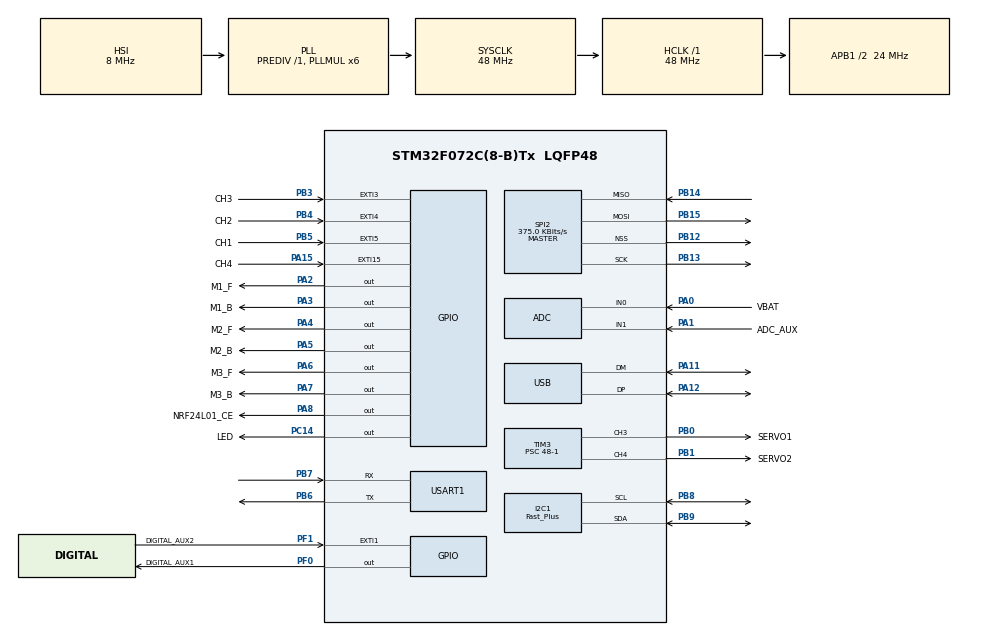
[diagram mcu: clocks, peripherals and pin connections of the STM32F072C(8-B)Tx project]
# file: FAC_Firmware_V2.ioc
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ADC.ContinuousConvMode=ENABLE
ADC.DMAContinuousRequests=ENABLE
ADC.EOCSelection=ADC_EOC_SEQ_CONV
ADC.SamplingTime=ADC_SAMPLETIME_55CYCLES_5
Dma.ADC.0.Direction=DMA_PERIPH_TO_MEMORY
Dma.ADC.0.Instance=DMA1_Channel1
Dma.ADC.0.MemDataAlignment=DMA_MDATAALIGN_HALFWORD
Dma.ADC.0.MemInc=DMA_MINC_ENABLE
Dma.ADC.0.Mode=DMA_CIRCULAR
Dma.ADC.0.PeriphDataAlignment=DMA_PDATAALIGN_HALFWORD
Dma.ADC.0.PeriphInc=DMA_PINC_DISABLE
Dma.ADC.0.Priority=DMA_PRIORITY_LOW
Dma.Request0=ADC
Dma.Request1=TIM1_UP
Dma.TIM1_UP.1.Direction=DMA_MEMORY_TO_PERIPH
Dma.TIM1_UP.1.Instance=DMA1_Channel5
Dma.TIM1_UP.1.MemDataAlignment=DMA_MDATAALIGN_WORD
Dma.TIM1_UP.1.MemInc=DMA_MINC_ENABLE
Dma.TIM1_UP.1.Mode=DMA_CIRCULAR
Dma.TIM1_UP.1.PeriphDataAlignment=DMA_PDATAALIGN_WORD
Dma.TIM1_UP.1.PeriphInc=DMA_PINC_DISABLE
Dma.TIM1_UP.1.Priority=DMA_PRIORITY_LOW
I2C1.I2C_Speed_Mode=I2C_Fast_Plus
I2C1.Timing=0x00100001
IWDG.Prescaler=IWDG_PRESCALER_32
IWDG.Reload=499
Mcu.Family=STM32F0
Mcu.Name=STM32F072C(8-B)Tx
Mcu.Package=LQFP48
NVIC.DMA1_Channel1_IRQn=true\:0\:0\:false\:false\:true\:false\:true\:true
NVIC.DMA1_Channel4_5_6_7_IRQn=true\:0\:0\:false\:false\:true\:false\:true\:true
NVIC.EXTI2_3_IRQn=true\:0\:0\:false\:false\:true\:true\:true\:true
NVIC.EXTI4_15_IRQn=true\:0\:0\:false\:false\:true\:true\:true\:true
NVIC.USB_IRQn=true\:0\:0\:false\:false\:true\:false\:true\:true
PA0.GPIO_Label=VBAT
PA0.Mode=IN0
PA0.Signal=ADC_IN0
PA1.GPIO_Label=ADC_AUX
PA1.Mode=IN1
PA1.Signal=ADC_IN1
PA11.Mode=Device
PA11.Signal=USB_DM
PA12.Mode=Device
PA12.Signal=USB_DP
PA13.Mode=Serial_Wire
PA13.Signal=SYS_SWDIO
PA14.Mode=Serial_Wire
PA14.Signal=SYS_SWCLK
PA15.GPIO_Label=CH4
PA15.GPIO_ModeDefaultEXTI=GPIO_MODE_IT_RISING_FALLING
PA15.Signal=GPXTI15
PA2.GPIO_Label=M1_F
PA2.Signal=GPIO_Output
PA3.GPIO_Label=M1_B
PA3.Signal=GPIO_Output
PA4.GPIO_Label=M2_F
PA4.Signal=GPIO_Output
PA5.GPIO_Label=M2_B
PA5.Signal=GPIO_Output
PA6.GPIO_Label=M3_F
PA6.Signal=GPIO_Output
PA7.GPIO_Label=M3_B
PA7.Signal=GPIO_Output
PA8.GPIO_Label=NRF24L01_CE
PA8.Signal=GPIO_Output
PB0.GPIO_Label=SERVO1
PB0.Signal=S_TIM3_CH3
PB1.GPIO_Label=SERVO2
PB1.Signal=S_TIM3_CH4
PB12.Mode=NSS_Signal_Hard_Output
PB12.Signal=SPI2_NSS
PB13.Mode=Full_Duplex_Master
PB13.Signal=SPI2_SCK
PB14.Mode=Full_Duplex_Master
PB14.Signal=SPI2_MISO
PB15.Mode=Full_Duplex_Master
PB15.Signal=SPI2_MOSI
PB3.GPIO_Label=CH3
PB3.GPIO_ModeDefaultEXTI=GPIO_MODE_IT_RISING_FALLING
PB3.Signal=GPXTI3
PB4.GPIO_Label=CH2
PB4.GPIO_ModeDefaultEXTI=GPIO_MODE_IT_RISING_FALLING
PB4.Signal=GPXTI4
PB5.GPIO_Label=CH1
PB5.GPIO_ModeDefaultEXTI=GPIO_MODE_IT_RISING_FALLING
PB5.Signal=GPXTI5
PB6.Mode=Asynchronous
PB6.Signal=USART1_TX
PB7.Mode=Asynchronous
PB7.Signal=USART1_RX
PB8.GPIO_FM8=__NULL
PB8.GPIO_Pu=GPIO_NOPULL
PB8.Mode=I2C
PB8.Signal=I2C1_SCL
PB9.GPIO_FM9=__NULL
PB9.GPIO_Pu=GPIO_NOPULL
PB9.Mode=I2C
PB9.Signal=I2C1_SDA
PC14-OSC32_IN.GPIO_Label=LED
PC14-OSC32_IN.Signal=GPIO_Output
PF0-OSC_IN.GPIO_Label=DIGITAL_AUX1
PF0-OSC_IN.Signal=GPIO_Output
PF1-OSC_OUT.GPIO_Label=DIGITAL_AUX2
PF1-OSC_OUT.Signal=GPXTI1
ProjectManager.HeapSize=0x200
ProjectManager.StackSize=0x400
ProjectManager.TargetToolchain=STM32CubeIDE
RCC.AHBFreq_Value=48000000
RCC.APB1CLKDivider=RCC_HCLK_DIV2
RCC.APB1Freq_Value=24000000
RCC.APB1TimFreq_Value=48000000
RCC.HCLKFreq_Value=48000000
RCC.PLLMUL=RCC_PLL_MUL6
RCC.SYSCLKFreq_VALUE=48000000
RCC.SYSCLKSource=RCC_SYSCLKSOURCE_PLLCLK
SH.S_TIM3_CH3.0=TIM3_CH3,PWM Generation3 CH3
SH.S_TIM3_CH4.0=TIM3_CH4,PWM Generation4 CH4
SPI2.BaudRatePrescaler=SPI_BAUDRATEPRESCALER_64
SPI2.CalculateBaudRate=375.0 KBits/s
SPI2.Direction=SPI_DIRECTION_2LINES
SPI2.Mode=SPI_MODE_MASTER
SPI2.VirtualNSS=VM_NSSHARD
SPI2.VirtualType=VM_MASTER
TIM1.TIM_MasterOutputTrigger=TIM_TRGO_UPDATE
TIM2.Prescaler=24-1
TIM3.Channel-PWM\ Generation3\ CH3=TIM_CHANNEL_3
TIM3.Channel-PWM\ Generation4\ CH4=TIM_CHANNEL_4
TIM3.Period=20000-1
TIM3.Prescaler=48-1
USART1.VirtualMode-Asynchronous=VM_ASYNC
USB_DEVICE.CLASS_NAME_FS=CDC
USB_DEVICE.MANUFACTURER_STRING=Floppy Lab
USB_DEVICE.PRODUCT_STRING_CDC_FS=FAC_V2
USB_DEVICE.VirtualMode=Cdc
USB_DEVICE.VirtualModeFS=Cdc_FS
VP_ADC_Vref_Input.Mode=IN-Vrefint
VP_IWDG_VS_IWDG.Mode=IWDG_Activate
VP_TIM1_VS_ClockSourceINT.Mode=Internal
VP_TIM2_VS_ClockSourceINT.Mode=Internal
VP_TIM3_VS_ClockSourceINT.Mode=Internal
VP_USB_DEVICE_VS_USB_DEVICE_CDC_FS.Mode=CDC_FS
board=custom

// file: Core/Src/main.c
/* USER CODE BEGIN Header */
/**
 ******************************************************************************
 * @file           : main.c
 * @brief          : Main program body
 ******************************************************************************
 * @attention
 *
 * Copyright (c) 2025 STMicroelectronics.
 * All rights reserved.
 *
 * This software is licensed under terms that can be found in the LICENSE file
 * in the root directory of this software component.
 * If no LICENSE file comes with this software, it is provided AS-IS.
 *
 ******************************************************************************
 */
/* USER CODE END Header */
#include "main.h"
#include "adc.h"
#include "dma.h"
#include "i2c.h"
#include "iwdg.h"
#include "spi.h"
#include "tim.h"
#include "usart.h"
#include "usb_device.h"
#include "gpio.h"

/* USER CODE BEGIN Includes */
#include "FAC_Code/fac_app.h"

/* FOR DEBUG AND TESTS */
//#include "FAC_Code/fac_adc.h"
//#include "FAC_Code/fac_motors.h"
//#include "FAC_Code/fac_battery.h"
//#include "FAC_Code/fac_std_receiver.h"
//#include "FAC_Code/fac_servo.h"
//#include "FAC_Code/fac_eeprom.h"
//#include "jingles/notes.h"
//#include "jingles/fac_jingles.h"
/* USER CODE END Includes */

/* USER CODE BEGIN PV */

/* debug variables */
uint8_t batType = 0;
uint16_t vbat = 0;
uint16_t adcCh0 = 0;
uint16_t adcCh1 = 0;
uint16_t chs[8];
uint16_t dataW = 43690;
uint16_t dataR = 0;
/* USER CODE END PV */

void SystemClock_Config(void);

/**FAC_battery_SET_calibration_offset(FAC_settings_GET_value(FAC_SETTINGS_CODE_BA11TTERY_CALIBRATION));
  * @brief  The application entry point.
  * @retval int11
  */
int main(void)
{

  /* MCU Configuration--------------------------------------------------------*/

  /* Reset of all peripherals, Initializes the Flash interface and the Systick. */
  HAL_Init();

  /* USER CODE BEGIN Init */
  __HAL_DBGMCU_FREEZE_IWDG();	// disable watchdog if core frozen (debug)
  /* USER CODE END Init */

  /* Configure the system clock */
  SystemClock_Config();

  /* Initialize all configured peripherals */
  MX_GPIO_Init();
  MX_DMA_Init();
  MX_ADC_Init();
  MX_I2C1_Init();
  MX_SPI2_Init();
  MX_USART1_UART_Init();
  MX_TIM1_Init();
  MX_TIM3_Init();
  MX_TIM2_Init();
  MX_USB_DEVICE_Init();
  MX_IWDG_Init();
  /* USER CODE BEGIN 2 */
	FAC_app_init();
  /* USER CODE END 2 */

  /* Infinite loop */
  /* USER CODE BEGIN WHILE */
	while (1) {
		FAC_app_main_loop();
    /* USER CODE END WHILE */

	}
}

void SystemClock_Config(void)
{
  RCC_OscInitTypeDef RCC_OscInitStruct = {0};
  RCC_ClkInitTypeDef RCC_ClkInitStruct = {0};
  RCC_PeriphCLKInitTypeDef PeriphClkInit = {0};

  /** Initializes the RCC Oscillators according to the specified parameters
  * in the RCC_OscInitTypeDef structure.
  */
  RCC_OscInitStruct.OscillatorType = RCC_OSCILLATORTYPE_HSI|RCC_OSCILLATORTYPE_HSI14
                              |RCC_OSCILLATORTYPE_HSI48|RCC_OSCILLATORTYPE_LSI;
  RCC_OscInitStruct.HSIState = RCC_HSI_ON;
  RCC_OscInitStruct.HSI48State = RCC_HSI48_ON;
  RCC_OscInitStruct.HSI14State = RCC_HSI14_ON;
  RCC_OscInitStruct.HSICalibrationValue = RCC_HSICALIBRATION_DEFAULT;
  RCC_OscInitStruct.HSI14CalibrationValue = 16;
  RCC_OscInitStruct.LSIState = RCC_LSI_ON;
  RCC_OscInitStruct.PLL.PLLState = RCC_PLL_ON;
  RCC_OscInitStruct.PLL.PLLSource = RCC_PLLSOURCE_HSI;
  RCC_OscInitStruct.PLL.PLLMUL = RCC_PLL_MUL6;
  RCC_OscInitStruct.PLL.PREDIV = RCC_PREDIV_DIV1;
  if (HAL_RCC_OscConfig(&RCC_OscInitStruct) != HAL_OK)
  {
    Error_Handler();
  }

  /** Initializes the CPU, AHB and APB buses clocks
  */
  RCC_ClkInitStruct.ClockType = RCC_CLOCKTYPE_HCLK|RCC_CLOCKTYPE_SYSCLK
                              |RCC_CLOCKTYPE_PCLK1;
  RCC_ClkInitStruct.SYSCLKSource = RCC_SYSCLKSOURCE_PLLCLK;
  RCC_ClkInitStruct.AHBCLKDivider = RCC_SYSCLK_DIV1;
  RCC_ClkInitStruct.APB1CLKDivider = RCC_HCLK_DIV2;

  if (HAL_RCC_ClockConfig(&RCC_ClkInitStruct, FLASH_LATENCY_1) != HAL_OK)
  {
    Error_Handler();
  }
  PeriphClkInit.PeriphClockSelection = RCC_PERIPHCLK_USB|RCC_PERIPHCLK_USART1
                              |RCC_PERIPHCLK_I2C1;
  PeriphClkInit.Usart1ClockSelection = RCC_USART1CLKSOURCE_PCLK1;
  PeriphClkInit.I2c1ClockSelection = RCC_I2C1CLKSOURCE_HSI;
  PeriphClkInit.UsbClockSelection = RCC_USBCLKSOURCE_HSI48;

  if (HAL_RCCEx_PeriphCLKConfig(&PeriphClkInit) != HAL_OK)
  {
    Error_Handler();
  }
}

void Error_Handler(void)
{
	__disable_irq();
	while (1) {
	}
}
